# S6E2CCxJ register map
Vendor: Cypress; File version: 2.0
CPU: CM4 r0p1, little endian, MPU, FPU, 4 interrupt priority bits
Registers are 32-bit, read-write, reset 0x0 unless marked. A register's access mark holds for its fields unless they carry their own. Offsets are from the block's base; [hi:lo] are bit positions; {n}, {i} and the like mark numbered series.

## CRTRIM — CR Trimming Registers
Base 0x4002E000
0x00 MCR_PSR 8-bit reset 0x1 — High-speed CR oscillation Frequency Division Setup Register
  [2:0] CSR — High-speed CR oscillation frequency division ratio setting bits
0x04 MCR_FTRM reset 0x1EF — High-speed CR oscillation Frequency Trimming Register
  [9:0] TRD — Frequency trimming setup bits
0x08 MCR_TTRM reset 0x10 — High-speed CR oscillation Temperature Trimming Register
  [4:0] TRT — Temperature trimming setup bits
0x0C MCR_RLR reset 0x1 — High-Speed CR Oscillation Register Write-Protect Register
  [31:0] TRMLCK — Register write-protect bits

## EXTI — External Interrupt and NMI Control
Base 0x40030000
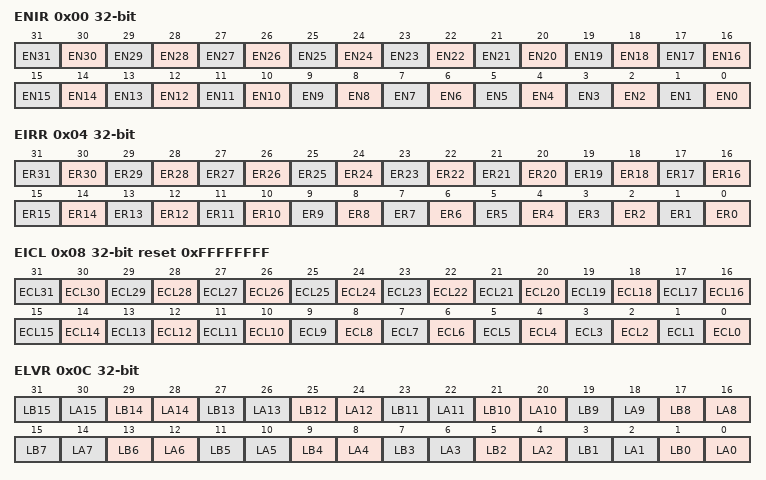
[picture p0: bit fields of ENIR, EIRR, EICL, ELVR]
0x00 ENIR — Enable Interrupt Request Register
  [n] EN{n} (n=0..31) — Bit{n} of ENIR
0x04 EIRR ro reset not defined — External Interrupt Request Register
  [n] ER{n} (n=0..31) — Bit{n} of EIRR
0x08 EICL reset 0xFFFFFFFF — External Interrupt Clear Register
  [n] ECL{n} (n=0..31) — Bit{n} of EICL
0x0C ELVR — External Interrupt Level Register
  [2n+1] LB{n} (n=0..15) — Bit{2n+1} of ELVR
  [2n] LA{n} (n=0..15) — Bit{2n} of ELVR
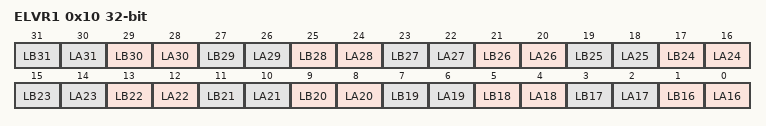
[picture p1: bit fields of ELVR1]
0x10 ELVR1 — External Interrupt Level Register 1
  [2n-31] LB{n} (n=16..31) — Bit{2n-31} of ELVR1
  [2n-32] LA{n} (n=16..31) — Bit{2n-32} of ELVR1
0x14 NMIRR 16-bit ro — Non Maskable Interrupt Request Register
  [0] NR — NMI interrupt request detection bit
0x18 NMICL 16-bit reset 0x1 — Non Maskable Interrupt Clear Register
  [0] NCL — NMI interrupt cause clear bit

## DAC0 — D/A Converter 0
Base 0x40033000
Same registers: DAC1 0x40033008
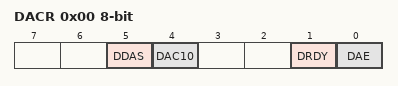
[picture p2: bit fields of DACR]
0x00 DACR 8-bit — D/A Control Register
  [5] DDAS — 10-bit mode data allocation selection bit
  [4] DAC10 — 10-bit mode
  [1] DRDY ro — D/A converter operation enable state bit
  [0] DAE — D/A converter operating enable bit
0x04 DADR 16-bit reset not defined — D/A Data Register
  [11:0] DA

## LVD — Low-voltage Detection
Base 0x40035000
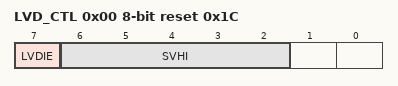
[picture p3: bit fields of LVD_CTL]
0x00 LVD_CTL 8-bit reset 0x1C — Low-voltage Detection Voltage Control Register
  [7] LVDIE — Low-voltage detection interrupt enable bit
  [6:2] SVHI — Low-voltage detection interrupt voltage setting bits
0x04 LVD_STR 8-bit ro — Low-voltage Detection Interrupt Factor Register
  [7] LVDIR — Low-voltage detection interrupt factor bit
0x08 LVD_CLR 8-bit reset 0x80 — Low-voltage Detection Interrupt Factor Clear Register
  [7] LVDCL — Low-voltage detection interrupt factor clear bit
0x0C LVD_RLR reset 0x1 — Low-voltage Detection Voltage Protection Register
  [31:0] LVDLCK — Low-voltage Detection Voltage Control Register protection bits
0x10 LVD_STR2 8-bit ro — Low-voltage Detection Circuit Status Register
  [7] LVDIRDY — Low-voltage detection interrupt status flag

## DS — Low Power Consumption Mode
Base 0x40035100
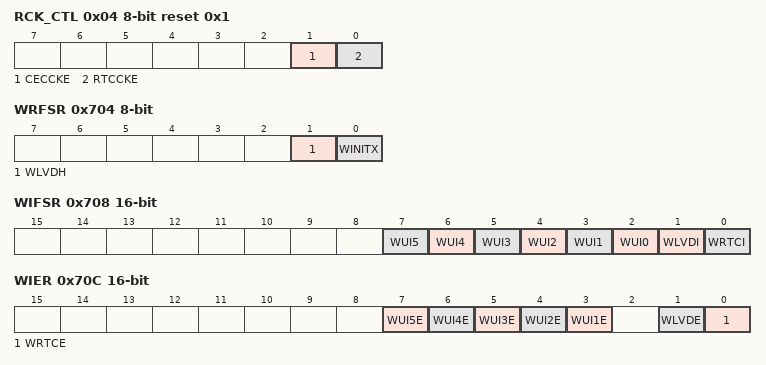
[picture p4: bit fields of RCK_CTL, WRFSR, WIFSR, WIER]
0x04 RCK_CTL 8-bit reset 0x1 — Sub Clock Control Register
  [1] CECCKE — CEC clock control bit
  [0] RTCCKE — RTC clock control bit
0x700 PMD_CTL 8-bit — RTC Mode Control Register
  [0] RTCE — RTC mode control bit
0x704 WRFSR 8-bit ro — Deep Standby Return Cause Register 1
  [1] WLVDH — Low-voltage detection reset return bit
  [0] WINITX — INITX pin input reset return bit
0x708 WIFSR 16-bit ro — Deep Standby Return Cause Register 2
  [n+2] WUI{n} (n=0..5) — WKUP pin input return bit {n}
  [1] WLVDI — LVD interrupt return bit
  [0] WRTCI — RTC interrupt return bit
0x70C WIER 16-bit — Deep Standby Return Enable Register
  [n+2] WUI{n}E (n=1..5) — WKUP pin input return enable bit {n}
  [1] WLVDE — LVD interrupt return enable bit
  [0] WRTCE — RTC interrupt return enable bit
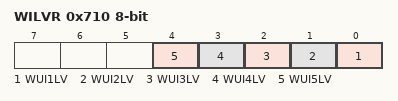
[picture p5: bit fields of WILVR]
0x710 WILVR 8-bit — WKUP Pin Input Level Register
  [n-1] WUI{n}LV (n=1..5) — WKUP pin input level select bit {n}
0x714 DSRAMR 8-bit — Deep Standby RAM Retention Register
  [1:0] SRAMR — On-chip SRAM retention control bits
{0x7FF+i} BUR{i:02} 8-bit (i=1..16) — Backup Registers from {i}
